AUTOSAR XML (schema 00044)
standard types defined: boolean, sint8, uint16, uint8, boolean_CompuMethod, boolean_DataConstr, sint8_DataConstr, uint16_DataConstr
package /ComponentTypes
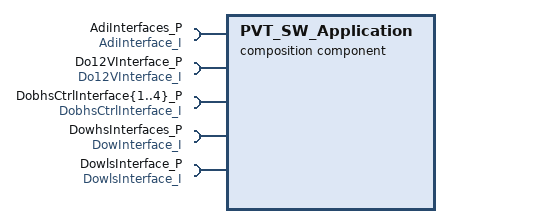
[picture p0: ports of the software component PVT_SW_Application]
  composition sw component type PVT_SW_Application
    8 x require port:
      AdiInterfaces_P: required-com-specs=[GetAdiPinState, GetAdiPinStateAll, GetPullUpState, SetPullUp], required-interface=AdiInterface_I
      Do12VInterface_P: required-com-specs=[GetDo12VPinsState, SetDcdc12VActive, SetDo12VLivingActive, SetDo12VParkedActive], required-interface=Do12VInterface_I
      DobhsCtrlInterface{1..4}_P: required-com-specs=[GetDobhsPinState, SetDobhsActive], required-interface=DobhsCtrlInterface_I
      DowhsInterfaces_P: required-com-specs=[DowInterface_I/GetDoPinStateOne, SetDowActive], required-interface=DowInterface_I
      DowlsInterface_P: required-com-specs=[DowlsInterface_I/GetDoPinStateOne, SetDowlsActive], required-interface=DowlsInterface_I
package /PortInterfaces
  5 x client server interface:
    AdiInterface_I
      4 x operation:
        GetAdiPinState
          arg AdiPinRef: type=uint8, direction=IN, server-argument-impl-policy=USE-ARGUMENT-TYPE
          arg AdiPinVoltage: type=VGTT_EcuPinVoltage_0V2, direction=OUT, server-argument-impl-policy=USE-ARGUMENT-TYPE
          arg PullUpVoltage: type=VGTT_EcuPinVoltage_0V2, direction=OUT, server-argument-impl-policy=USE-ARGUMENT-TYPE
        GetAdiPinStateAll
          arg VoltageOnAdiPins: type=VGTT_ScimAdiPinsState, direction=OUT, server-argument-impl-policy=USE-ARGUMENT-TYPE
          arg PullUpVoltage: type=VGTT_EcuPinVoltage_0V2, direction=OUT, server-argument-impl-policy=USE-ARGUMENT-TYPE
        GetPullUpState
          arg PullUpVoltage_Living: type=VGTT_EcuPinVoltage_0V2, direction=OUT, server-argument-impl-policy=USE-ARGUMENT-TYPE
          arg PullUpVoltage_Parked: type=VGTT_EcuPinVoltage_0V2, direction=OUT, server-argument-impl-policy=USE-ARGUMENT-TYPE
        SetPullUp
          arg ActivateLivingPullUp: type=boolean, direction=IN, server-argument-impl-policy=USE-ARGUMENT-TYPE
          arg ActivateParkedPullUp: type=boolean, direction=IN, server-argument-impl-policy=USE-ARGUMENT-TYPE
    Do12VInterface_I
      4 x operation:
        GetDo12VPinsState
          6 x arg, all with server-argument-impl-policy=USE-ARGUMENT-TYPE:
            SelectParkedOrLivingPin: type=uint8, direction=IN
            IsDo12VActivated: type=boolean, direction=OUT
            BatteryVoltage: type=VGTT_EcuPinVoltage_0V2, direction=OUT
            DcdcRefVoltage: type=VGTT_EcuPinVoltage_0V2, direction=OUT
            Do12VPinVoltage: type=VGTT_EcuPinVoltage_0V2, direction=OUT
            DiagStatus: type=VGTT_EcuPinDiagStatus, direction=OUT
        SetDcdc12VActive
          arg Activation: type=boolean, direction=IN, server-argument-impl-policy=USE-ARGUMENT-TYPE
        SetDo12VLivingActive
          arg Activation: type=boolean, direction=IN, server-argument-impl-policy=USE-ARGUMENT-TYPE
        SetDo12VParkedActive
          arg Activation: type=boolean, direction=IN, server-argument-impl-policy=USE-ARGUMENT-TYPE
    DobhsCtrlInterface_I
      operation GetDobhsPinState
        4 x arg, all with direction=OUT, server-argument-impl-policy=USE-ARGUMENT-TYPE:
          IsDoActivated: type=boolean
          DoPinVoltage: type=VGTT_EcuPinVoltage_0V2
          BatteryVoltage: type=VGTT_EcuPinVoltage_0V2
          DiagStatus: type=VGTT_EcuPinDiagStatus
      operation SetDobhsActive
        arg Activation: type=boolean, direction=IN, server-argument-impl-policy=USE-ARGUMENT-TYPE
    DowInterface_I
      operation GetDoPinStateOne
        7 x arg, all with server-argument-impl-policy=USE-ARGUMENT-TYPE:
          DoPinRef: type=uint8, direction=IN
          IsDoActivated: type=boolean, direction=OUT
          DoPinVoltage: type=VGTT_EcuPinVoltage_0V2, direction=OUT
          BatteryVoltage: type=VGTT_EcuPinVoltage_0V2, direction=OUT
          DutyCycle: type=sint8, direction=OUT
          Period: type=uint16, direction=OUT
          DiagStatus: type=VGTT_EcuPinDiagStatus, direction=OUT
      operation SetDowActive
        arg OutputId: type=uint8, direction=IN, server-argument-impl-policy=USE-ARGUMENT-TYPE
        arg Period: type=uint16, direction=IN, server-argument-impl-policy=USE-ARGUMENT-TYPE
        arg DutyCycle: type=sint8, direction=IN, server-argument-impl-policy=USE-ARGUMENT-TYPE
    DowlsInterface_I
      operation GetDoPinStateOne
        7 x arg, all with server-argument-impl-policy=USE-ARGUMENT-TYPE:
          DoPinRef: type=uint8, direction=IN
          IsDoActivated: type=boolean, direction=OUT
          DoPinVoltage: type=VGTT_EcuPinVoltage_0V2, direction=OUT
          BatteryVoltage: type=VGTT_EcuPinVoltage_0V2, direction=OUT
          DutyCycle: type=sint8, direction=OUT
          Period: type=uint16, direction=OUT
          DiagStatus: type=VGTT_EcuPinDiagStatus, direction=OUT
      operation SetDowlsActive
        arg OutputId: type=uint8, direction=IN, server-argument-impl-policy=USE-ARGUMENT-TYPE
        arg Period: type=uint16, direction=IN, server-argument-impl-policy=USE-ARGUMENT-TYPE
        arg DutyCycle: type=sint8, direction=IN, server-argument-impl-policy=USE-ARGUMENT-TYPE
package /SCIM_DataTypes
  impl type VGTT_EcuPinDiagStatus: category=VALUE, base-type=uint8, range raw 0..255, invalid-value=254  # Diagnostic status: accordingly to FTB definition +. 11 = STG; 12 = STB; 13 = OC; 16 = VBT; 17 = VAT; 0xF0 = NotExecuted; 0xFD = CircuitNotPopulated; 0xFE = ERROR; 0xFF = NotAvailable;
  impl type VGTT_EcuPinVoltage_0V2: category=VALUE, base-type=uint8, range raw 0..255, invalid-value=254  # Voltage value with resolution of 0.2V: 0..250 = 0..50V; 251..253 = reserved; 254 = Error; 255 = NotAvailable;
  impl type VGTT_ScimAdiPinsState: category=ARRAY
    element AdiPin: category=VALUE, array-size=15, array-size-semantics=FIXED-SIZE, base-type=uint8, sw-calibration-access=READ-ONLY, range raw 0..255
